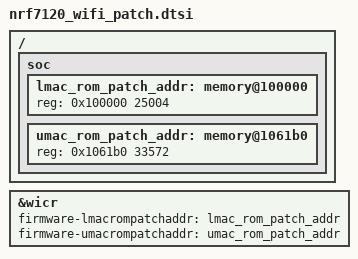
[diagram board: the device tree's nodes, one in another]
/*
 * Copyright (c) 2026 Nordic Semiconductor ASA
 *
 * SPDX-License-Identifier: LicenseRef-Nordic-5-Clause
 */

/ {
	soc {
		lmac_rom_patch_addr: memory@100000 {
			reg = <0x100000 25004>;
		};

		umac_rom_patch_addr: memory@1061b0 {
			reg = <0x1061b0 33572>;
		};
	};
};

&wicr {
	firmware-lmacrompatchaddr = <&lmac_rom_patch_addr>;
	firmware-umacrompatchaddr = <&umac_rom_patch_addr>;
};
